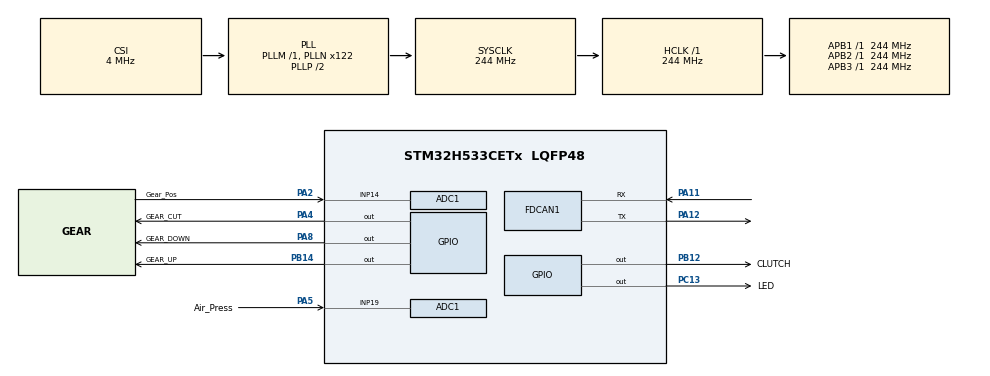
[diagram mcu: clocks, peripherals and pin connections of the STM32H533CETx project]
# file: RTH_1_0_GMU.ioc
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ADC1.Channel-0\#ChannelRegularConversion=ADC_CHANNEL_14
ADC1.Channel-1\#ChannelRegularConversion=ADC_CHANNEL_19
ADC1.ContinuousConvMode=ENABLE
ADC1.DMAContinuousRequests=ENABLE
ADC1.EOCSelection=ADC_EOC_SEQ_CONV
ADC1.MonitoredBy-0\#ChannelRegularConversion=__NULL
ADC1.MonitoredBy-1\#ChannelRegularConversion=__NULL
ADC1.NbrOfConversion=2
ADC1.NbrOfConversionFlag=1
ADC1.OffsetNumber-0\#ChannelRegularConversion=ADC_OFFSET_NONE
ADC1.OffsetNumber-1\#ChannelRegularConversion=ADC_OFFSET_NONE
ADC1.Overrun=ADC_OVR_DATA_OVERWRITTEN
ADC1.OversamplingMode=DISABLE
ADC1.Rank-0\#ChannelRegularConversion=1
ADC1.Rank-1\#ChannelRegularConversion=2
ADC1.SamplingTime-0\#ChannelRegularConversion=ADC_SAMPLETIME_92CYCLES_5
ADC1.SamplingTime-1\#ChannelRegularConversion=ADC_SAMPLETIME_92CYCLES_5
ADC1.master=1
BOOTPATH.BootPathName=LEGACY
BOOTPATH.UserSelectedBootPath=LEGACY
CORTEX_M33_NS.userName=CORTEX_M33
FDCAN1.AutoRetransmission=ENABLE
FDCAN1.CalculateBaudRateNominal=500000
FDCAN1.CalculateTimeBitNominal=2000
FDCAN1.CalculateTimeQuantumNominal=20.0
FDCAN1.DataPrescaler=25
FDCAN1.DataTimeSeg1=2
FDCAN1.NominalPrescaler=2
FDCAN1.NominalSyncJumpWidth=13
FDCAN1.NominalTimeSeg1=86
FDCAN1.NominalTimeSeg2=13
GPDMA1.CIRCULARMODE_GPDMACH7=ENABLE
GPDMA1.DESTDATAWIDTH_GPDMACH7=DMA_DEST_DATAWIDTH_HALFWORD
GPDMA1.DESTINC_GPDMACH7=DMA_DINC_INCREMENTED
GPDMA1.IPHANDLE_GPDMACH7-SIMPLEREQUEST_GPDMACH7=__NULL
GPDMA1.REQUEST_GPDMACH7=GPDMA1_REQUEST_ADC1
GPDMA1.SRCDATAWIDTH_GPDMACH7=DMA_SRC_DATAWIDTH_HALFWORD
Mcu.Family=STM32H5
Mcu.Name=STM32H533CETx
Mcu.Package=LQFP48
NVIC.ADC1_IRQn=true\:0\:0\:false\:false\:true\:true\:true\:true
NVIC.FDCAN1_IT0_IRQn=true\:0\:0\:false\:false\:true\:true\:true\:true
NVIC.FDCAN1_IT1_IRQn=true\:0\:0\:false\:false\:true\:true\:true\:true
NVIC.GPDMA1_Channel7_IRQn=true\:0\:0\:false\:false\:true\:false\:true\:true
NVIC.PriorityGroup=NVIC_PRIORITYGROUP_4
PA11.Mode=FDCAN_Activate
PA11.Signal=FDCAN1_RX
PA12.Mode=FDCAN_Activate
PA12.Signal=FDCAN1_TX
PA13(JTMS/SWDIO).Mode=Serial_Wire
PA13(JTMS/SWDIO).Signal=DEBUG_JTMS-SWDIO
PA14(JTCK/SWCLK).Mode=Serial_Wire
PA14(JTCK/SWCLK).Signal=DEBUG_JTCK-SWCLK
PA2.GPIO_Label=Gear_Pos
PA2.Signal=ADCx_INP14
PA4.GPIO_Label=GEAR_CUT
PA4.Signal=GPIO_Output
PA5.GPIO_Label=Air_Press
PA5.Signal=ADCx_INP19
PA8.GPIO_Label=GEAR_DOWN
PA8.Signal=GPIO_Output
PB12.GPIO_Label=CLUTCH
PB12.Signal=GPIO_Output
PB14.GPIO_Label=GEAR_UP
PB14.Signal=GPIO_Output
PC13.GPIO_Label=LED
PC13.Signal=GPIO_Output
ProjectManager.HeapSize=0x200
ProjectManager.StackSize=0x400
ProjectManager.TargetToolchain=STM32CubeIDE
RCC.ADCCLockSelection=RCC_ADCDACCLKSOURCE_CSI
RCC.ADCFreq_Value=4000000
RCC.AHBFreq_Value=244000000
RCC.APB1Freq_Value=244000000
RCC.APB1TimFreq_Value=244000000
RCC.APB2Freq_Value=244000000
RCC.APB2TimFreq_Value=244000000
RCC.APB3Freq_Value=244000000
RCC.CSI_VALUE=4000000
RCC.CortexFreq_Value=244000000
RCC.EPOD_VALUE=4000000
RCC.FDCANClockSelection=RCC_FDCANCLKSOURCE_PLL2Q
RCC.HCLKFreq_Value=244000000
RCC.HSE_VALUE=25000000
RCC.HSI48_VALUE=48000000
RCC.HSI_VALUE=64000000
RCC.LSE_VALUE=32768
RCC.LSIRC_VALUE=32000
RCC.PLL2FRACN=0
RCC.PLL2M=2
RCC.PLL2N=150
RCC.PLL2Q=3
RCC.PLL3FRACN=0
RCC.PLLFRACN=0
RCC.PLLN=122
RCC.SYSCLKFreq_VALUE=244000000
RCC.SYSCLKSource=RCC_SYSCLKSOURCE_PLLCLK
RCC.USBFreq_Value=48000000
RCC.VCOOutputFreq_Value=488000000
SH.ADCx_INP14.0=ADC1_INP14,IN14-Single-Ended
SH.ADCx_INP19.0=ADC1_INP19,IN19-Single-Ended
VP_BOOTPATH_VS_BOOTPATH.Mode=BP_Activate
VP_CORTEX_M33_NS_VS_Hclk.Mode=Hclk_Mode
VP_GPDMA1_VS_GPDMACH7.Mode=SIMPLEREQUEST_GPDMACH7
VP_MEMORYMAP_VS_MEMORYMAP.Mode=CurAppReg
VP_PWR_VS_DBSignals.Mode=DisableDeadBatterySignals
VP_PWR_VS_LPOM.Mode=PowerOptimisation
VP_PWR_VS_SECSignals.Mode=Security/Privilege
board=custom

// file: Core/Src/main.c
/* USER CODE BEGIN Header */
/**
  ******************************************************************************
  * @file           : main.c
  * @brief          : Main program body
  ******************************************************************************
  * @attention
  *
  * Copyright (c) 2024 STMicroelectronics.
  * All rights reserved.
  *
  * This software is licensed under terms that can be found in the LICENSE file
  * in the root directory of this software component.
  * If no LICENSE file comes with this software, it is provided AS-IS.
  *
  ******************************************************************************
  */
/* USER CODE END Header */
#include "main.h"

ADC_HandleTypeDef hadc1;
DMA_NodeTypeDef Node_GPDMA1_Channel7;
DMA_QListTypeDef List_GPDMA1_Channel7;
DMA_HandleTypeDef handle_GPDMA1_Channel7;

FDCAN_HandleTypeDef hfdcan1;

void SystemClock_Config(void);
static void MX_GPIO_Init(void);
static void MX_GPDMA1_Init(void);
static void MX_ADC1_Init(void);
static void MX_FDCAN1_Init(void);

int main(void)
{

  /* MCU Configuration--------------------------------------------------------*/

  /* Reset of all peripherals, Initializes the Flash interface and the Systick. */
  HAL_Init();

  /* Configure the system clock */
  SystemClock_Config();

  /* Initialize all configured peripherals */
  MX_GPIO_Init();
  MX_GPDMA1_Init();
  MX_ADC1_Init();
  MX_FDCAN1_Init();
  /* USER CODE BEGIN 2 */
  AppInit(&hadc1,&hfdcan1);
  AppHandle();
  /* USER CODE END 2 */

  /* Infinite loop */
  while (1)
  {

  }
}

void SystemClock_Config(void)
{
  RCC_OscInitTypeDef RCC_OscInitStruct = {0};
  RCC_ClkInitTypeDef RCC_ClkInitStruct = {0};

  /** Configure the main internal regulator output voltage
  */
  __HAL_PWR_VOLTAGESCALING_CONFIG(PWR_REGULATOR_VOLTAGE_SCALE0);

  while(!__HAL_PWR_GET_FLAG(PWR_FLAG_VOSRDY)) {}

  /** Initializes the RCC Oscillators according to the specified parameters
  * in the RCC_OscInitTypeDef structure.
  */
  RCC_OscInitStruct.OscillatorType = RCC_OSCILLATORTYPE_CSI;
  RCC_OscInitStruct.CSIState = RCC_CSI_ON;
  RCC_OscInitStruct.CSICalibrationValue = RCC_CSICALIBRATION_DEFAULT;
  RCC_OscInitStruct.PLL.PLLState = RCC_PLL_ON;
  RCC_OscInitStruct.PLL.PLLSource = RCC_PLL1_SOURCE_CSI;
  RCC_OscInitStruct.PLL.PLLM = 1;
  RCC_OscInitStruct.PLL.PLLN = 122;
  RCC_OscInitStruct.PLL.PLLP = 2;
  RCC_OscInitStruct.PLL.PLLQ = 2;
  RCC_OscInitStruct.PLL.PLLR = 2;
  RCC_OscInitStruct.PLL.PLLRGE = RCC_PLL1_VCIRANGE_2;
  RCC_OscInitStruct.PLL.PLLVCOSEL = RCC_PLL1_VCORANGE_WIDE;
  RCC_OscInitStruct.PLL.PLLFRACN = 0;
  if (HAL_RCC_OscConfig(&RCC_OscInitStruct) != HAL_OK)
  {
    Error_Handler();
  }

  /** Initializes the CPU, AHB and APB buses clocks
  */
  RCC_ClkInitStruct.ClockType = RCC_CLOCKTYPE_HCLK|RCC_CLOCKTYPE_SYSCLK
                              |RCC_CLOCKTYPE_PCLK1|RCC_CLOCKTYPE_PCLK2
                              |RCC_CLOCKTYPE_PCLK3;
  RCC_ClkInitStruct.SYSCLKSource = RCC_SYSCLKSOURCE_PLLCLK;
  RCC_ClkInitStruct.AHBCLKDivider = RCC_SYSCLK_DIV1;
  RCC_ClkInitStruct.APB1CLKDivider = RCC_HCLK_DIV1;
  RCC_ClkInitStruct.APB2CLKDivider = RCC_HCLK_DIV1;
  RCC_ClkInitStruct.APB3CLKDivider = RCC_HCLK_DIV1;

  if (HAL_RCC_ClockConfig(&RCC_ClkInitStruct, FLASH_LATENCY_5) != HAL_OK)
  {
    Error_Handler();
  }

  /** Configure the programming delay
  */
  __HAL_FLASH_SET_PROGRAM_DELAY(FLASH_PROGRAMMING_DELAY_2);
}

static void MX_ADC1_Init(void)
{

  ADC_ChannelConfTypeDef sConfig = {0};

  /** Common config
  */
  hadc1.Instance = ADC1;
  hadc1.Init.ClockPrescaler = ADC_CLOCK_ASYNC_DIV1;
  hadc1.Init.Resolution = ADC_RESOLUTION_12B;
  hadc1.Init.DataAlign = ADC_DATAALIGN_RIGHT;
  hadc1.Init.ScanConvMode = ADC_SCAN_ENABLE;
  hadc1.Init.EOCSelection = ADC_EOC_SEQ_CONV;
  hadc1.Init.LowPowerAutoWait = DISABLE;
  hadc1.Init.ContinuousConvMode = ENABLE;
  hadc1.Init.NbrOfConversion = 2;
  hadc1.Init.DiscontinuousConvMode = DISABLE;
  hadc1.Init.ExternalTrigConv = ADC_SOFTWARE_START;
  hadc1.Init.ExternalTrigConvEdge = ADC_EXTERNALTRIGCONVEDGE_NONE;
  hadc1.Init.DMAContinuousRequests = ENABLE;
  hadc1.Init.SamplingMode = ADC_SAMPLING_MODE_NORMAL;
  hadc1.Init.Overrun = ADC_OVR_DATA_OVERWRITTEN;
  hadc1.Init.OversamplingMode = DISABLE;
  if (HAL_ADC_Init(&hadc1) != HAL_OK)
  {
    Error_Handler();
  }

  /** Configure Regular Channel
  */
  sConfig.Channel = ADC_CHANNEL_14;
  sConfig.Rank = ADC_REGULAR_RANK_1;
  sConfig.SamplingTime = ADC_SAMPLETIME_92CYCLES_5;
  sConfig.SingleDiff = ADC_SINGLE_ENDED;
  sConfig.OffsetNumber = ADC_OFFSET_NONE;
  sConfig.Offset = 0;
  if (HAL_ADC_ConfigChannel(&hadc1, &sConfig) != HAL_OK)
  {
    Error_Handler();
  }

  /** Configure Regular Channel
  */
  sConfig.Channel = ADC_CHANNEL_19;
  sConfig.Rank = ADC_REGULAR_RANK_2;
  if (HAL_ADC_ConfigChannel(&hadc1, &sConfig) != HAL_OK)
  {
    Error_Handler();
  }

}

static void MX_FDCAN1_Init(void)
{

  hfdcan1.Instance = FDCAN1;
  hfdcan1.Init.ClockDivider = FDCAN_CLOCK_DIV1;
  hfdcan1.Init.FrameFormat = FDCAN_FRAME_CLASSIC;
  hfdcan1.Init.Mode = FDCAN_MODE_NORMAL;
  hfdcan1.Init.AutoRetransmission = ENABLE;
  hfdcan1.Init.TransmitPause = DISABLE;
  hfdcan1.Init.ProtocolException = DISABLE;
  hfdcan1.Init.NominalPrescaler = 2;
  hfdcan1.Init.NominalSyncJumpWidth = 13;
  hfdcan1.Init.NominalTimeSeg1 = 86;
  hfdcan1.Init.NominalTimeSeg2 = 13;
  hfdcan1.Init.DataPrescaler = 25;
  hfdcan1.Init.DataSyncJumpWidth = 1;
  hfdcan1.Init.DataTimeSeg1 = 2;
  hfdcan1.Init.DataTimeSeg2 = 1;
  hfdcan1.Init.StdFiltersNbr = 0;
  hfdcan1.Init.ExtFiltersNbr = 0;
  hfdcan1.Init.TxFifoQueueMode = FDCAN_TX_FIFO_OPERATION;
  if (HAL_FDCAN_Init(&hfdcan1) != HAL_OK)
  {
    Error_Handler();
  }

}

static void MX_GPDMA1_Init(void)
{

  /* Peripheral clock enable */
  __HAL_RCC_GPDMA1_CLK_ENABLE();

  /* GPDMA1 interrupt Init */
    HAL_NVIC_SetPriority(GPDMA1_Channel7_IRQn, 0, 0);
    HAL_NVIC_EnableIRQ(GPDMA1_Channel7_IRQn);

}

static void MX_GPIO_Init(void)
{
  GPIO_InitTypeDef GPIO_InitStruct = {0};

  /* GPIO Ports Clock Enable */
  __HAL_RCC_GPIOC_CLK_ENABLE();
  __HAL_RCC_GPIOA_CLK_ENABLE();
  __HAL_RCC_GPIOB_CLK_ENABLE();

  /*Configure GPIO pin Output Level */
  HAL_GPIO_WritePin(LED_GPIO_Port, LED_Pin, GPIO_PIN_RESET);

  /*Configure GPIO pin Output Level */
  HAL_GPIO_WritePin(GPIOA, GEAR_CUT_Pin|GEAR_DOWN_Pin, GPIO_PIN_RESET);

  /*Configure GPIO pin Output Level */
  HAL_GPIO_WritePin(GPIOB, CLUTCH_Pin|GEAR_UP_Pin, GPIO_PIN_RESET);

  /*Configure GPIO pin : LED_Pin */
  GPIO_InitStruct.Pin = LED_Pin;
  GPIO_InitStruct.Mode = GPIO_MODE_OUTPUT_PP;
  GPIO_InitStruct.Pull = GPIO_NOPULL;
  GPIO_InitStruct.Speed = GPIO_SPEED_FREQ_LOW;
  HAL_GPIO_Init(LED_GPIO_Port, &GPIO_InitStruct);

  /*Configure GPIO pins : GEAR_CUT_Pin GEAR_DOWN_Pin */
  GPIO_InitStruct.Pin = GEAR_CUT_Pin|GEAR_DOWN_Pin;
  GPIO_InitStruct.Mode = GPIO_MODE_OUTPUT_PP;
  GPIO_InitStruct.Pull = GPIO_NOPULL;
  GPIO_InitStruct.Speed = GPIO_SPEED_FREQ_LOW;
  HAL_GPIO_Init(GPIOA, &GPIO_InitStruct);

  /*Configure GPIO pins : CLUTCH_Pin GEAR_UP_Pin */
  GPIO_InitStruct.Pin = CLUTCH_Pin|GEAR_UP_Pin;
  GPIO_InitStruct.Mode = GPIO_MODE_OUTPUT_PP;
  GPIO_InitStruct.Pull = GPIO_NOPULL;
  GPIO_InitStruct.Speed = GPIO_SPEED_FREQ_LOW;
  HAL_GPIO_Init(GPIOB, &GPIO_InitStruct);

}

void Error_Handler(void)
{
  __disable_irq();
  while (1)
  {
  }
}
